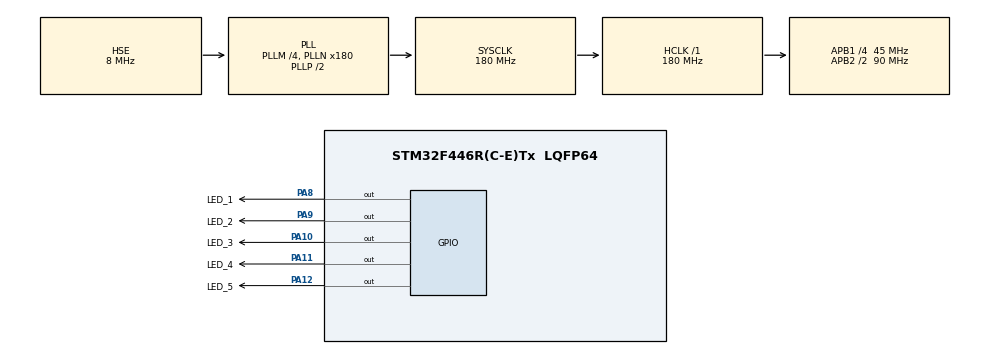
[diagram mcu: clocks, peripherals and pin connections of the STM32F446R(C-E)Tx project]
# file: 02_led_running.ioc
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Mcu.Family=STM32F4
Mcu.Name=STM32F446R(C-E)Tx
Mcu.Package=LQFP64
NVIC.PriorityGroup=NVIC_PRIORITYGROUP_4
PA10.GPIO_Label=LED_3
PA10.Signal=GPIO_Output
PA11.GPIO_Label=LED_4
PA11.Signal=GPIO_Output
PA12.GPIO_Label=LED_5
PA12.Signal=GPIO_Output
PA13.Mode=Serial_Wire
PA13.Signal=SYS_JTMS-SWDIO
PA14.Mode=Serial_Wire
PA14.Signal=SYS_JTCK-SWCLK
PA8.GPIO_Label=LED_1
PA8.Signal=GPIO_Output
PA9.GPIO_Label=LED_2
PA9.Signal=GPIO_Output
PH0-OSC_IN.Mode=HSE-External-Clock-Source
PH0-OSC_IN.Signal=RCC_OSC_IN
PH1-OSC_OUT.Mode=HSE-External-Clock-Source
PH1-OSC_OUT.Signal=RCC_OSC_OUT
ProjectManager.HeapSize=0x200
ProjectManager.StackSize=0x400
ProjectManager.TargetToolchain=CMake
RCC.AHBFreq_Value=180000000
RCC.APB1CLKDivider=RCC_HCLK_DIV4
RCC.APB1Freq_Value=45000000
RCC.APB1TimFreq_Value=90000000
RCC.APB2CLKDivider=RCC_HCLK_DIV2
RCC.APB2Freq_Value=90000000
RCC.APB2TimFreq_Value=180000000
RCC.CortexFreq_Value=180000000
RCC.HCLKFreq_Value=180000000
RCC.HSE_VALUE=8000000
RCC.PLLM=4
RCC.PLLN=180
RCC.PLLSourceVirtual=RCC_PLLSOURCE_HSE
RCC.SYSCLKFreq_VALUE=180000000
RCC.SYSCLKSource=RCC_SYSCLKSOURCE_PLLCLK
RCC.USBFreq_Value=180000000
RCC.VCOOutputFreq_Value=360000000
board=custom

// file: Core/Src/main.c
/* USER CODE BEGIN Header */
/**
 ******************************************************************************
 * @file           : main.c
 * @brief          : Main program body
 ******************************************************************************
 * @attention
 *
 * Copyright (c) 2026 STMicroelectronics.
 * All rights reserved.
 *
 * This software is licensed under terms that can be found in the LICENSE file
 * in the root directory of this software component.
 * If no LICENSE file comes with this software, it is provided AS-IS.
 *
 ******************************************************************************
 */
/* USER CODE END Header */
#include "main.h"
#include "stm32f4xx_hal_gpio.h"

/* USER CODE BEGIN PV */
GPIO_TypeDef *led_ports[] = {LED_1_GPIO_Port, LED_2_GPIO_Port, LED_3_GPIO_Port,
                             LED_4_GPIO_Port, LED_5_GPIO_Port};

uint16_t led_pins[] = {LED_1_Pin, LED_2_Pin, LED_3_Pin, LED_4_Pin, LED_5_Pin};
/* USER CODE END PV */

void SystemClock_Config(void);
static void MX_GPIO_Init(void);

int main(void)
{

  /* MCU Configuration--------------------------------------------------------*/

  /* Reset of all peripherals, Initializes the Flash interface and the Systick. */
  HAL_Init();

  /* Configure the system clock */
  SystemClock_Config();

  /* Initialize all configured peripherals */
  MX_GPIO_Init();
  /* USER CODE BEGIN 2 */
  const uint8_t count = sizeof(led_ports) / sizeof(led_ports[0]);
  /* USER CODE END 2 */

  /* Infinite loop */
  /* USER CODE BEGIN WHILE */
  while (1) {
    for (uint8_t i = 0; i < count; i++) {
      HAL_GPIO_WritePin(led_ports[i], led_pins[i], GPIO_PIN_SET);
      HAL_Delay(100);
      HAL_GPIO_WritePin(led_ports[i], led_pins[i], GPIO_PIN_RESET);
    }

    for (int i = (int)count - 2; i >= 1; i--) {
      HAL_GPIO_WritePin(led_ports[i], led_pins[i], GPIO_PIN_SET);
      HAL_Delay(100);
      HAL_GPIO_WritePin(led_ports[i], led_pins[i], GPIO_PIN_RESET);
    }

    /* USER CODE END WHILE */

  }
}

void SystemClock_Config(void)
{
  RCC_OscInitTypeDef RCC_OscInitStruct = {0};
  RCC_ClkInitTypeDef RCC_ClkInitStruct = {0};

  /** Configure the main internal regulator output voltage
  */
  __HAL_RCC_PWR_CLK_ENABLE();
  __HAL_PWR_VOLTAGESCALING_CONFIG(PWR_REGULATOR_VOLTAGE_SCALE1);

  /** Initializes the RCC Oscillators according to the specified parameters
  * in the RCC_OscInitTypeDef structure.
  */
  RCC_OscInitStruct.OscillatorType = RCC_OSCILLATORTYPE_HSE;
  RCC_OscInitStruct.HSEState = RCC_HSE_BYPASS;
  RCC_OscInitStruct.PLL.PLLState = RCC_PLL_ON;
  RCC_OscInitStruct.PLL.PLLSource = RCC_PLLSOURCE_HSE;
  RCC_OscInitStruct.PLL.PLLM = 4;
  RCC_OscInitStruct.PLL.PLLN = 180;
  RCC_OscInitStruct.PLL.PLLP = RCC_PLLP_DIV2;
  RCC_OscInitStruct.PLL.PLLQ = 2;
  RCC_OscInitStruct.PLL.PLLR = 2;
  if (HAL_RCC_OscConfig(&RCC_OscInitStruct) != HAL_OK)
  {
    Error_Handler();
  }

  /** Activate the Over-Drive mode
  */
  if (HAL_PWREx_EnableOverDrive() != HAL_OK)
  {
    Error_Handler();
  }

  /** Initializes the CPU, AHB and APB buses clocks
  */
  RCC_ClkInitStruct.ClockType = RCC_CLOCKTYPE_HCLK|RCC_CLOCKTYPE_SYSCLK
                              |RCC_CLOCKTYPE_PCLK1|RCC_CLOCKTYPE_PCLK2;
  RCC_ClkInitStruct.SYSCLKSource = RCC_SYSCLKSOURCE_PLLCLK;
  RCC_ClkInitStruct.AHBCLKDivider = RCC_SYSCLK_DIV1;
  RCC_ClkInitStruct.APB1CLKDivider = RCC_HCLK_DIV4;
  RCC_ClkInitStruct.APB2CLKDivider = RCC_HCLK_DIV2;

  if (HAL_RCC_ClockConfig(&RCC_ClkInitStruct, FLASH_LATENCY_5) != HAL_OK)
  {
    Error_Handler();
  }
}

static void MX_GPIO_Init(void)
{
  GPIO_InitTypeDef GPIO_InitStruct = {0};

  /* GPIO Ports Clock Enable */
  __HAL_RCC_GPIOH_CLK_ENABLE();
  __HAL_RCC_GPIOA_CLK_ENABLE();

  /*Configure GPIO pin Output Level */
  HAL_GPIO_WritePin(GPIOA, LED_1_Pin|LED_2_Pin|LED_3_Pin|LED_4_Pin
                          |LED_5_Pin, GPIO_PIN_RESET);

  /*Configure GPIO pins : LED_1_Pin LED_2_Pin LED_3_Pin LED_4_Pin
                           LED_5_Pin */
  GPIO_InitStruct.Pin = LED_1_Pin|LED_2_Pin|LED_3_Pin|LED_4_Pin
                          |LED_5_Pin;
  GPIO_InitStruct.Mode = GPIO_MODE_OUTPUT_PP;
  GPIO_InitStruct.Pull = GPIO_NOPULL;
  GPIO_InitStruct.Speed = GPIO_SPEED_FREQ_LOW;
  HAL_GPIO_Init(GPIOA, &GPIO_InitStruct);

}

void Error_Handler(void)
{
  __disable_irq();
  while (1) {
  }
}
#ifdef USE_FULL_ASSERT
/**
  * @brief  Reports the name of the source file and the source line number
  *         where the assert_param error has occurred.
  * @param  file: pointer to the source file name
  * @param  line: assert_param error line source number
  * @retval None
  */
void assert_failed(uint8_t *file, uint32_t line)
{
  /* USER CODE BEGIN 6 */
  /* User can add his own implementation to report the file name and line
     number, ex: printf("Wrong parameters value: file %s on line %d\r\n", file,
     line) */
  /* USER CODE END 6 */
}
#endif /* USE_FULL_ASSERT */
